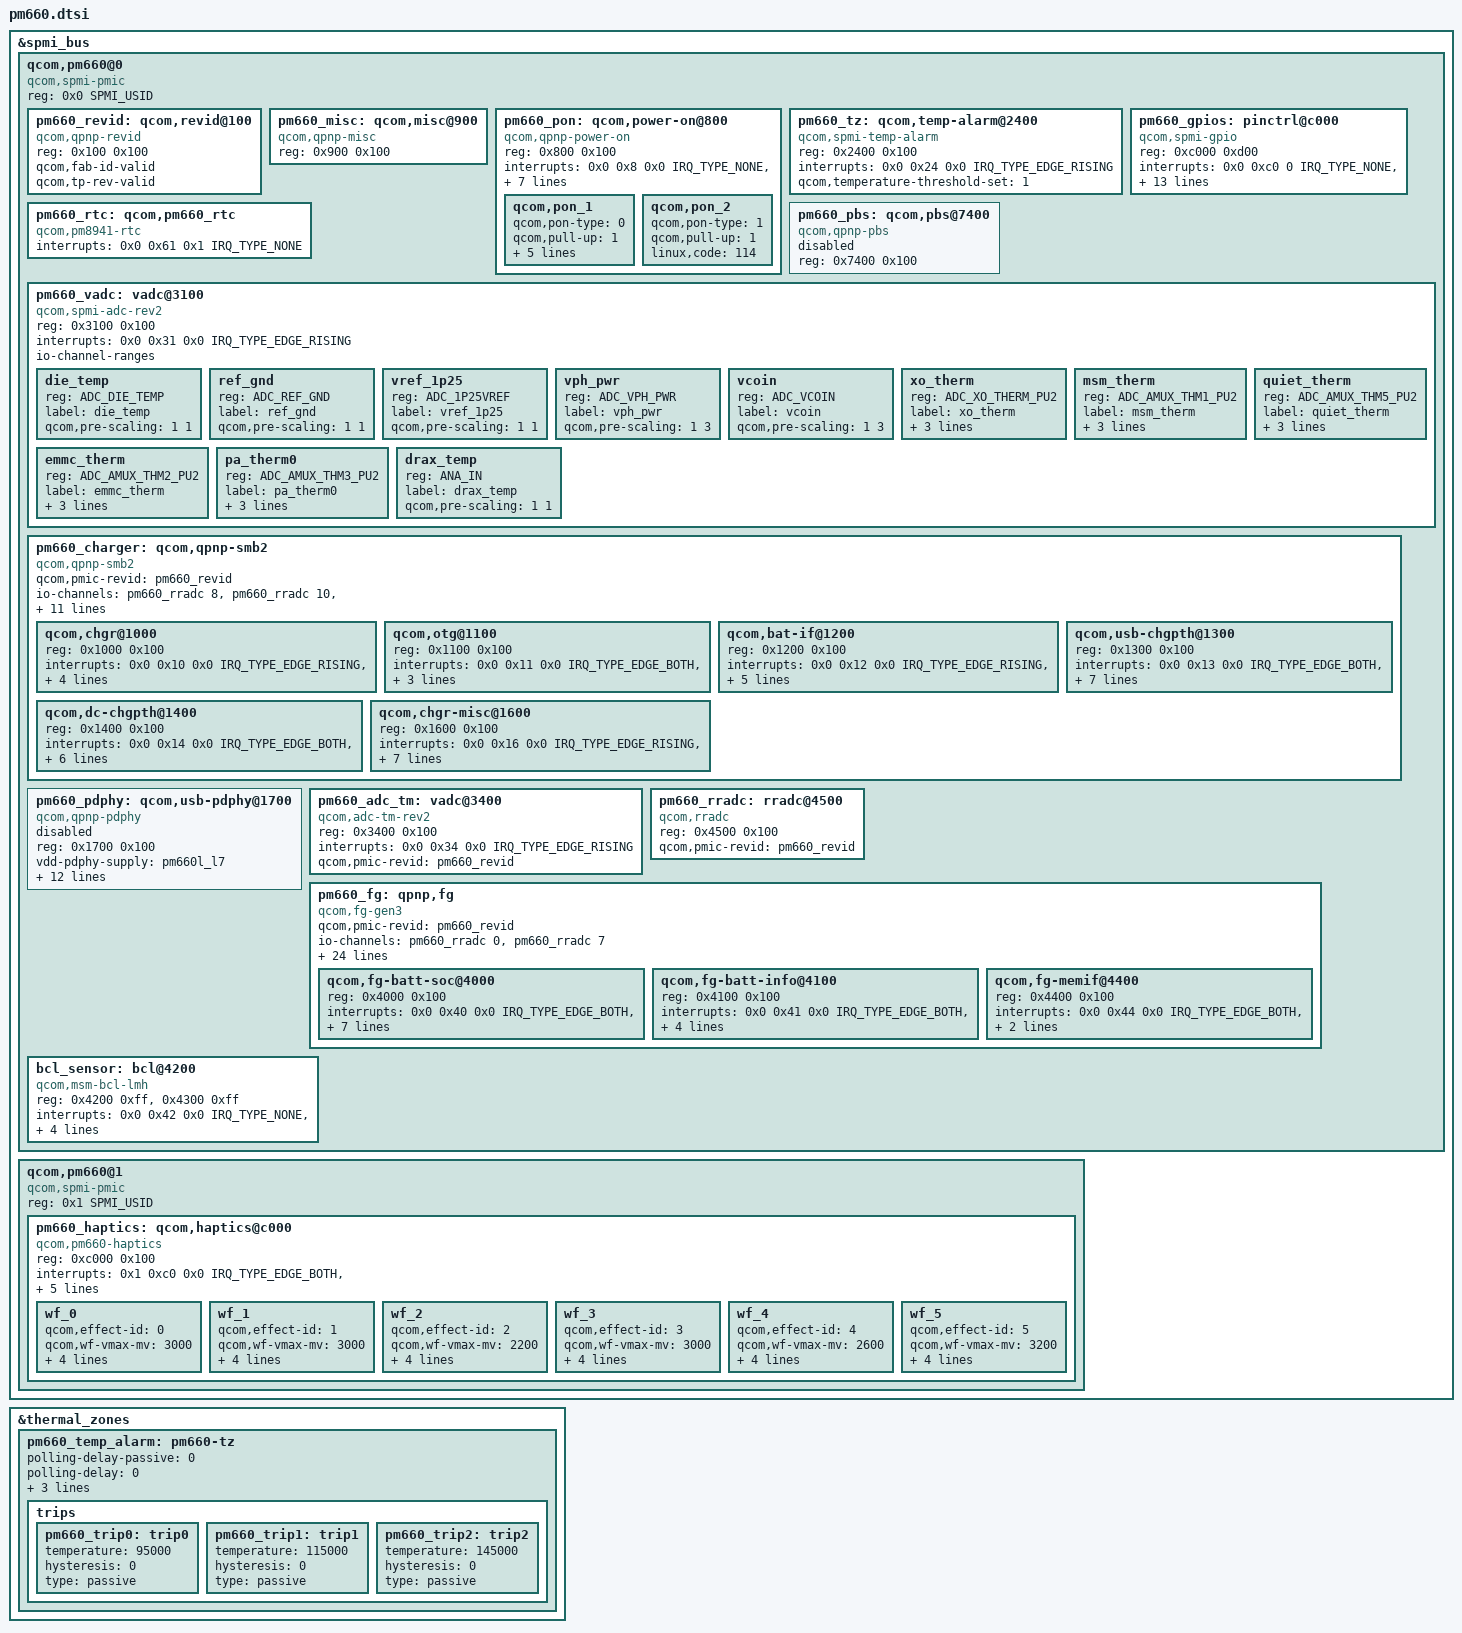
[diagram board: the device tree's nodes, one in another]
#include <dt-bindings/spmi/spmi.h>
#include <dt-bindings/iio/qcom,spmi-vadc.h>
#include <dt-bindings/interrupt-controller/irq.h>

&spmi_bus {
	qcom,pm660@0 {
		compatible ="qcom,spmi-pmic";
		reg = <0x0 SPMI_USID>;
		#address-cells = <2>;
		#size-cells = <0>;

		pm660_revid: qcom,revid@100 {
			compatible = "qcom,qpnp-revid";
			reg = <0x100 0x100>;
			qcom,fab-id-valid;
			qcom,tp-rev-valid;
		};

		pm660_misc: qcom,misc@900 {
			compatible = "qcom,qpnp-misc";
			reg = <0x900 0x100>;
		};

		pm660_pon: qcom,power-on@800 {
			compatible = "qcom,qpnp-power-on";
			reg = <0x800 0x100>;
			interrupts = <0x0 0x8 0x0 IRQ_TYPE_NONE>,
				     <0x0 0x8 0x1 IRQ_TYPE_NONE>,
				     <0x0 0x8 0x4 IRQ_TYPE_NONE>,
				     <0x0 0x8 0x5 IRQ_TYPE_NONE>;
			interrupt-names = "kpdpwr", "resin",
					"resin-bark", "kpdpwr-resin-bark";
			qcom,pon-dbc-delay = <15625>;
			qcom,kpdpwr-sw-debounce;
			qcom,system-reset;
			qcom,store-hard-reset-reason;

			qcom,pon_1 {
				qcom,pon-type = <0>;
				qcom,pull-up = <1>;
				linux,code = <116>;
			/* Huaqin add for ZQL1650-14 by lanshiming at 2018/1/17 start*/
				qcom,support-reset = <1>;
				qcom,s1-timer = <10256>;
				qcom,s2-timer = <10>;
				qcom,s2-type = <4>;
			/* Huaqin add for ZQL1650-14 by lanshiming at 2018/1/17 end*/
			};

			qcom,pon_2 {
				qcom,pon-type = <1>;
				qcom,pull-up = <1>;
				linux,code = <114>;
			};
		};

		pm660_tz: qcom,temp-alarm@2400 {
			compatible = "qcom,spmi-temp-alarm";
			reg = <0x2400 0x100>;
			interrupts = <0x0 0x24 0x0 IRQ_TYPE_EDGE_RISING>;
			#thermal-sensor-cells = <0>;
			qcom,temperature-threshold-set = <1>;
		};

		pm660_gpios: pinctrl@c000 {
			compatible = "qcom,spmi-gpio";
			reg = <0xc000 0xd00>;
			interrupts = <0x0 0xc0 0 IRQ_TYPE_NONE>,
					<0x0 0xc1 0 IRQ_TYPE_NONE>,
					<0x0 0xc2 0 IRQ_TYPE_NONE>,
					<0x0 0xc3 0 IRQ_TYPE_NONE>,
					<0x0 0xc4 0 IRQ_TYPE_NONE>,
					<0x0 0xc5 0 IRQ_TYPE_NONE>,
					<0x0 0xc6 0 IRQ_TYPE_NONE>,
					<0x0 0xc7 0 IRQ_TYPE_NONE>,
					<0x0 0xc8 0 IRQ_TYPE_NONE>,
					<0x0 0xc9 0 IRQ_TYPE_NONE>,
					<0x0 0xca 0 IRQ_TYPE_NONE>,
					<0x0 0xcb 0 IRQ_TYPE_NONE>,
					<0x0 0xcc 0 IRQ_TYPE_NONE>;
			interrupt-names = "pm660_gpio1", "pm660_gpio2",
					"pm660_gpio3", "pm660_gpio4",
					"pm660_gpio5", "pm660_gpio6",
					"pm660_gpio7", "pm660_gpio8",
					"pm660_gpio9", "pm660_gpio10",
					"pm660_gpio11", "pm660_gpio12",
					"pm660_gpio13";
			gpio-controller;
			#gpio-cells = <2>;
		};

		pm660_rtc: qcom,pm660_rtc {
			compatible = "qcom,pm8941-rtc";
			interrupts = <0x0 0x61 0x1 IRQ_TYPE_NONE>;
		};

		pm660_pbs: qcom,pbs@7400 {
			compatible = "qcom,qpnp-pbs";
			reg = <0x7400 0x100>;
			status = "disabled";
		};

		pm660_vadc: vadc@3100 {
			compatible = "qcom,spmi-adc-rev2";
			reg = <0x3100 0x100>;
			#address-cells = <1>;
			#size-cells = <0>;
			interrupts = <0x0 0x31 0x0 IRQ_TYPE_EDGE_RISING>;
			interrupt-names = "eoc-int-en-set";
			#io-channel-cells = <1>;
			io-channel-ranges;

			/* Channel nodes */
			die_temp {
				reg = <ADC_DIE_TEMP>;
				label = "die_temp";
				qcom,pre-scaling = <1 1>;
			};

			ref_gnd {
				reg = <ADC_REF_GND>;
				label = "ref_gnd";
				qcom,pre-scaling = <1 1>;
			};

			vref_1p25 {
				reg = <ADC_1P25VREF>;
				label = "vref_1p25";
				qcom,pre-scaling = <1 1>;
			};


			vph_pwr {
				reg = <ADC_VPH_PWR>;
				label = "vph_pwr";
				qcom,pre-scaling = <1 3>;
			};

			vcoin {
				reg = <ADC_VCOIN>;
				label = "vcoin";
				qcom,pre-scaling = <1 3>;
			};

			xo_therm {
				reg = <ADC_XO_THERM_PU2>;
				label = "xo_therm";
				qcom,ratiometric;
				qcom,hw-settle-time = <200>;
				qcom,pre-scaling = <1 1>;
			};

			msm_therm{
				reg = <ADC_AMUX_THM1_PU2>;
				label = "msm_therm";
				qcom,ratiometric;
				qcom,hw-settle-time = <200>;
				qcom,pre-scaling = <1 1>;
			};

			quiet_therm{
				reg = <ADC_AMUX_THM5_PU2>;
				label = "quiet_therm";
				qcom,ratiometric;
				qcom,hw-settle-time = <200>;
				qcom,pre-scaling = <1 1>;
			};

			emmc_therm{
				reg = <ADC_AMUX_THM2_PU2>;
				label = "emmc_therm";
				qcom,ratiometric;
				qcom,hw-settle-time = <200>;
				qcom,pre-scaling = <1 1>;
			};

			pa_therm0{
				reg = <ADC_AMUX_THM3_PU2>;
				label = "pa_therm0";
				qcom,ratiometric;
				qcom,hw-settle-time = <200>;
				qcom,pre-scaling = <1 1>;
			};

			drax_temp{
				reg = <ANA_IN>;
				label = "drax_temp";
				qcom,pre-scaling = <1 1>;
			};
		};

		pm660_charger: qcom,qpnp-smb2 {
			compatible = "qcom,qpnp-smb2";
			#address-cells = <1>;
			#size-cells = <1>;

			qcom,pmic-revid = <&pm660_revid>;

			io-channels = <&pm660_rradc 8>,
				      <&pm660_rradc 10>,
				      <&pm660_rradc 3>,
				      <&pm660_rradc 4>;
			io-channel-names = "charger_temp",
					   "charger_temp_max",
					   "usbin_i",
					   "usbin_v";

			qcom,wipower-max-uw = <5000000>;
			dpdm-supply = <&qusb_phy0>;

/* Huaqin modify for ZQL1650-70 Identify Adapter ID by fangaijun at 2018/02/8 start */
			qcom,thermal-mitigation
					= <3000000 2500000 2000000 1500000
						1000000 500000>;
/* Huaqin modify for ZQL1650-70 Identify Adapter ID by fangaijun at 2018/02/8 end */
			// Added by huqinmin remove Type-C for micro-usb 2018/1/31 begin
			qcom,use-extcon;
			// Added by huqinmin remove Type-C for micro-usb 2018/1/31 end
/* Huaqin modify for ZQL1650 by fangaijun  at 2018/02/2 start */
/* Huaqin modify for ZQL1650-70 optimize Adapter ID by fangaijun at 2018/02/9 start */
			qcom,fcc-max-ua = <2000000>;
/* Huaqin modify for ZQL1650-70 optimize Adapter ID by fangaijun at 2018/02/9 end */
			qcom,fv-max-uv = <4350000>;
/* Huaqin modify for ZQL1650-70 optimize Adapter ID by fangaijun at 2018/02/9 start */
			qcom,usb-icl-ua = <2000000>;
/* Huaqin modify for ZQL1650-70 optimize Adapter ID by fangaijun at 2018/02/9 end */
			qcom,float-option = <1>;
/* Huaqin modify for ZQL1650 by fangaijun  at 2018/02/2 end */
/* Huaqin modify for ZQL1650 recharge SOC and voltage by fangaijun at 2018/02/2 start */
			qcom,auto-recharge-soc;
/* Huaqin modify for ZQL1650 recharge SOC and voltage by fangaijun at 2018/02/2 end */
			qcom,chgr@1000 {
				reg = <0x1000 0x100>;
				interrupts =
					<0x0 0x10 0x0 IRQ_TYPE_EDGE_RISING>,
					<0x0 0x10 0x1 IRQ_TYPE_EDGE_RISING>,
					<0x0 0x10 0x2 IRQ_TYPE_EDGE_RISING>,
					<0x0 0x10 0x3 IRQ_TYPE_EDGE_RISING>,
					<0x0 0x10 0x4 IRQ_TYPE_EDGE_RISING>;

				interrupt-names = "chg-error",
						  "chg-state-change",
						  "step-chg-state-change",
						  "step-chg-soc-update-fail",
						  "step-chg-soc-update-request";
			};

			qcom,otg@1100 {
				reg = <0x1100 0x100>;
				interrupts = <0x0 0x11 0x0 IRQ_TYPE_EDGE_BOTH>,
					     <0x0 0x11 0x1 IRQ_TYPE_EDGE_BOTH>,
					     <0x0 0x11 0x2 IRQ_TYPE_EDGE_BOTH>,
					     <0x0 0x11 0x3 IRQ_TYPE_EDGE_BOTH>;

				interrupt-names = "otg-fail",
						  "otg-overcurrent",
						  "otg-oc-dis-sw-sts",
						  "testmode-change-detect";
			};

			qcom,bat-if@1200 {
				reg = <0x1200 0x100>;
				interrupts =
					<0x0 0x12 0x0 IRQ_TYPE_EDGE_RISING>,
					<0x0 0x12 0x1 IRQ_TYPE_EDGE_BOTH>,
					<0x0 0x12 0x2 IRQ_TYPE_EDGE_BOTH>,
					<0x0 0x12 0x3 IRQ_TYPE_EDGE_BOTH>,
					<0x0 0x12 0x4 IRQ_TYPE_EDGE_BOTH>,
					<0x0 0x12 0x5 IRQ_TYPE_EDGE_BOTH>;

				interrupt-names = "bat-temp",
						  "bat-ocp",
						  "bat-ov",
						  "bat-low",
						  "bat-therm-or-id-missing",
						  "bat-terminal-missing";
			};

			qcom,usb-chgpth@1300 {
				reg = <0x1300 0x100>;
				interrupts =
					<0x0 0x13 0x0 IRQ_TYPE_EDGE_BOTH>,
					<0x0 0x13 0x1 IRQ_TYPE_EDGE_BOTH>,
					<0x0 0x13 0x2 IRQ_TYPE_EDGE_BOTH>,
					<0x0 0x13 0x3 IRQ_TYPE_EDGE_BOTH>,
					<0x0 0x13 0x4 IRQ_TYPE_EDGE_BOTH>,
					<0x0 0x13 0x5 IRQ_TYPE_EDGE_RISING>,
					<0x0 0x13 0x6 IRQ_TYPE_EDGE_RISING>,
					<0x0 0x13 0x7 IRQ_TYPE_EDGE_RISING>;

				interrupt-names = "usbin-collapse",
						  "usbin-lt-3p6v",
						  "usbin-uv",
						  "usbin-ov",
						  "usbin-plugin",
						  "usbin-src-change",
						  "usbin-icl-change",
						  "type-c-change";
			};

			qcom,dc-chgpth@1400 {
				reg = <0x1400 0x100>;
				interrupts =
					<0x0 0x14 0x0 IRQ_TYPE_EDGE_BOTH>,
					<0x0 0x14 0x1 IRQ_TYPE_EDGE_BOTH>,
					<0x0 0x14 0x2 IRQ_TYPE_EDGE_BOTH>,
					<0x0 0x14 0x3 IRQ_TYPE_EDGE_BOTH>,
					<0x0 0x14 0x4 IRQ_TYPE_EDGE_BOTH>,
					<0x0 0x14 0x5 IRQ_TYPE_EDGE_BOTH>,
					<0x0 0x14 0x6 IRQ_TYPE_EDGE_RISING>;

				interrupt-names = "dcin-collapse",
						  "dcin-lt-3p6v",
						  "dcin-uv",
						  "dcin-ov",
						  "dcin-plugin",
						  "div2-en-dg",
						  "dcin-icl-change";
			};

			qcom,chgr-misc@1600 {
				reg = <0x1600 0x100>;
				interrupts =
					<0x0 0x16 0x0 IRQ_TYPE_EDGE_RISING>,
					<0x0 0x16 0x1 IRQ_TYPE_EDGE_RISING>,
					<0x0 0x16 0x2 IRQ_TYPE_EDGE_BOTH>,
					<0x0 0x16 0x3 IRQ_TYPE_EDGE_BOTH>,
					<0x0 0x16 0x4 IRQ_TYPE_EDGE_BOTH>,
					<0x0 0x16 0x5 IRQ_TYPE_EDGE_BOTH>,
					<0x0 0x16 0x6 IRQ_TYPE_EDGE_FALLING>,
					<0x0 0x16 0x7 IRQ_TYPE_EDGE_BOTH>;

				interrupt-names = "wdog-snarl",
						  "wdog-bark",
						  "aicl-fail",
						  "aicl-done",
						  "high-duty-cycle",
						  "input-current-limiting",
						  "temperature-change",
						  "switcher-power-ok";
			};
		};

		pm660_pdphy: qcom,usb-pdphy@1700 {
			compatible = "qcom,qpnp-pdphy";
			// Added by huqinmin remove Type-C for micro-usb 2018/1/31 begin
			/* Huaqin modify for ZQL1820-HQ000003 Optimize power consumption by diabling TYPE-C by gaochao at 2018/09/17 start */
			status = "disabled";
			/* Huaqin modify for ZQL1820-HQ000003 Optimize power consumption by diabling TYPE-C by gaochao at 2018/09/17 end */
			// Added by huqinmin remove Type-C for micro-usb 2018/1/31 end
			reg = <0x1700 0x100>;
			vdd-pdphy-supply = <&pm660l_l7>;
			vbus-supply = <&smb2_vbus>;
			vconn-supply = <&smb2_vconn>;
			interrupts = <0x0 0x17 0x0 IRQ_TYPE_EDGE_RISING>,
				     <0x0 0x17 0x1 IRQ_TYPE_EDGE_RISING>,
				     <0x0 0x17 0x2 IRQ_TYPE_EDGE_RISING>,
				     <0x0 0x17 0x3 IRQ_TYPE_EDGE_RISING>,
				     <0x0 0x17 0x4 IRQ_TYPE_EDGE_RISING>,
				     <0x0 0x17 0x5 IRQ_TYPE_EDGE_RISING>,
				     <0x0 0x17 0x6 IRQ_TYPE_EDGE_RISING>;

			interrupt-names = "sig-tx",
					  "sig-rx",
					  "msg-tx",
					  "msg-rx",
					  "msg-tx-failed",
					  "msg-tx-discarded",
					  "msg-rx-discarded";

			qcom,default-sink-caps = <5000 3000>, /* 5V @ 3A */
						 <9000 3000>; /* 9V @ 3A */
			qcom,no-usb3-dp-concurrency;
			qcom,pd-20-source-only;
		};

		pm660_adc_tm: vadc@3400 {
			compatible = "qcom,adc-tm-rev2";
			reg = <0x3400 0x100>;
			interrupts = <0x0 0x34 0x0 IRQ_TYPE_EDGE_RISING>;
			interrupt-names = "thr-int-en";
			#address-cells = <1>;
			#size-cells = <0>;
			#thermal-sensor-cells = <1>;
			qcom,pmic-revid = <&pm660_revid>;
		};

		pm660_rradc: rradc@4500 {
			compatible = "qcom,rradc";
			reg = <0x4500 0x100>;
			#address-cells = <1>;
			#size-cells = <0>;
			#io-channel-cells = <1>;
			qcom,pmic-revid = <&pm660_revid>;
		};

		pm660_fg: qpnp,fg {
			compatible = "qcom,fg-gen3";
			#address-cells = <1>;
			#size-cells = <1>;
			qcom,pmic-revid = <&pm660_revid>;
			io-channels = <&pm660_rradc 0>,
				      <&pm660_rradc 7>;
			io-channel-names = "rradc_batt_id",
					   "rradc_die_temp";
			qcom,rradc-base = <0x4500>;
			qcom,fg-esr-timer-awake = <96 96>;
/* Huaqin modify for ZQL1650-1244 A periodic pulse of 14s occurs when the phone idel by fangaijun  at 2018/05/14 start */
			qcom,fg-esr-timer-asleep = <160 256>;
/* Huaqin modify for ZQL1650-1244 A periodic pulse of 14s occurs when the phone idel by fangaijun  at 2018/05/14 end */
			qcom,fg-esr-timer-charging = <0 96>;
			qcom,cycle-counter-en;
/* Huaqin modify for ZQL1650 by fangaijun  at 2018/02/1 start */
			qcom,fg-cutoff-voltage = <3400>;
			qcom,fg-empty-voltage = <2800>;
/* Huaqin modify for ZQL1650 by fangaijun  at 2018/02/1 end */

/* Huaqin modify for ZQL1650 remove cc-cv voltage by fangaijun  at 2018/03/22 start */
			//qcom,fg-cc-cv-threshold-mv = <4340>;
/* Huaqin modify for ZQL1650 remove cc-cv voltage by fangaijun  at 2018/03/22 end */
/* Huaqin modify for ZQL1650-586 optimize low temperature discharging soc deviation by fangaijun  at 2018/03/22 start */
/* Huaqin modify for ZQL1650-1096 optimize normal temperature charging soc deviation by fangaijun  at 2018/04/27 start */
			qcom,fg-esr-tight-filter-micro-pct = <20000>;
			qcom,fg-esr-broad-filter-micro-pct = <25000>;
/* Huaqin modify for ZQL1650-1096 optimize normal temperature charging soc deviation by fangaijun  at 2018/04/27 end */
			qcom,fg-esr-tight-lt-filter-micro-pct = <2000>;
			qcom,fg-esr-broad-lt-filter-micro-pct = <2200>;
			qcom,slope-limit-temp-threshold = <150>;
			qcom,slope-limit-coeffs = <1 1 1 1>;
/* Huaqin modify for ZQL1650-586 optimize low temperature discharging soc deviation by fangaijun  at 2018/03/22 end */
/* Huaqin modify for ZQL1650 by fangaijun  at 2018/02/2 start */
			qcom,fg-chg-term-current = <150>;
			qcom,fg-sys-term-current = <(-200)>;
			qcom,hold-soc-while-full;
			qcom,linearize-soc;
			qcom,fg-force-load-profile;
/* Huaqin modify for ZQL1650 Realize HW Jeita by fangaijun  at 2018/02/6 start */
			/* Huaqin modify for ZQL1820-HQ000002  Adjust JEITA according to customer require by gaochao at 2018/10/11 start */
			//qcom,fg-jeita-thresholds = <0 1 59 60>;
			qcom,fg-jeita-thresholds = <0 1 54 55>;
			/* Huaqin modify for ZQL1820-HQ000002  Adjust JEITA according to customer require by gaochao at 2018/10/11 end */
			qcom,fg-jeita-hyst-temp = <3>;
/* Huaqin modify for ZQL1650 Realize HW Jeita by fangaijun  at 2018/02/6 end */
/* Huaqin modify for ZQL1650 by fangaijun  at 2018/02/2 end */
/* Huaqin modify for ZQL1650 recharge SOC and voltage by fangaijun at 2018/02/2 start */
			qcom,fg-recharge-voltage = <4150>;
			qcom,fg-recharge-soc-thr = <98>;
			qcom,fg-auto-recharge-soc;
/* Huaqin modify for ZQL1650 recharge SOC and voltage by fangaijun at 2018/02/2 end */
//Huaqin added by tangqingyong at 20180226 for fg use external start
			qcom,fg-rsense-sel=<1>;
//Huaqin added by tangqingyong at 20180226 for fg use external end
			status = "okay";

			qcom,fg-batt-soc@4000 {
				status = "okay";
				reg = <0x4000 0x100>;
				interrupts = <0x0 0x40 0x0 IRQ_TYPE_EDGE_BOTH>,
					     <0x0 0x40 0x1 IRQ_TYPE_EDGE_BOTH>,
					     <0x0 0x40 0x2
							IRQ_TYPE_EDGE_RISING>,
					     <0x0 0x40 0x3
							IRQ_TYPE_EDGE_RISING>,
					     <0x0 0x40 0x4 IRQ_TYPE_EDGE_BOTH>,
					     <0x0 0x40 0x5
							IRQ_TYPE_EDGE_RISING>,
					     <0x0 0x40 0x6 IRQ_TYPE_EDGE_BOTH>,
					     <0x0 0x40 0x7 IRQ_TYPE_EDGE_BOTH>;
				interrupt-names = "soc-update",
						  "soc-ready",
						  "bsoc-delta",
						  "msoc-delta",
						  "msoc-low",
						  "msoc-empty",
						  "msoc-high",
						  "msoc-full";
			};

			qcom,fg-batt-info@4100 {
				status = "okay";
				reg = <0x4100 0x100>;
				interrupts = <0x0 0x41 0x0 IRQ_TYPE_EDGE_BOTH>,
					     <0x0 0x41 0x1 IRQ_TYPE_EDGE_BOTH>,
					     <0x0 0x41 0x2 IRQ_TYPE_EDGE_BOTH>,
					     <0x0 0x41 0x3 IRQ_TYPE_EDGE_BOTH>,
					     <0x0 0x41 0x6 IRQ_TYPE_EDGE_BOTH>;
				interrupt-names = "vbatt-pred-delta",
						  "vbatt-low",
						  "esr-delta",
						  "batt-missing",
						  "batt-temp-delta";
			};

			qcom,fg-memif@4400 {
				status = "okay";
				reg = <0x4400 0x100>;
				interrupts = <0x0 0x44 0x0 IRQ_TYPE_EDGE_BOTH>,
					     <0x0 0x44 0x1 IRQ_TYPE_EDGE_BOTH>,
					     <0x0 0x44 0x2 IRQ_TYPE_EDGE_BOTH>;
				interrupt-names = "ima-rdy",
						  "mem-xcp",
						  "dma-grant";
			};
		};

		bcl_sensor:bcl@4200 {
			compatible = "qcom,msm-bcl-lmh";
			reg = <0x4200 0xff>,
				<0x4300 0xff>;
			reg-names = "fg_user_adc",
					"fg_lmh";
			interrupts = <0x0 0x42 0x0 IRQ_TYPE_NONE>,
					<0x0 0x42 0x1 IRQ_TYPE_NONE>,
					<0x0 0x42 0x2 IRQ_TYPE_NONE>,
					<0x0 0x42 0x3 IRQ_TYPE_NONE>,
					<0x0 0x42 0x4 IRQ_TYPE_NONE>;
			interrupt-names = "bcl-high-ibat",
						"bcl-very-high-ibat",
						"bcl-low-vbat",
						"bcl-very-low-vbat",
						"bcl-crit-low-vbat";
			#thermal-sensor-cells = <1>;
		};
	};

	qcom,pm660@1 {
		compatible ="qcom,spmi-pmic";
		reg = <0x1 SPMI_USID>;
		#address-cells = <2>;
		#size-cells = <0>;

		pm660_haptics: qcom,haptics@c000 {
			compatible = "qcom,pm660-haptics";
			reg = <0xc000 0x100>;
			reg-names = "haptics";
			status = "okay";

			interrupts = <0x1 0xc0 0x0 IRQ_TYPE_EDGE_BOTH>,
				     <0x1 0xc0 0x1 IRQ_TYPE_EDGE_BOTH>;
			interrupt-names = "hap-sc-irq", "hap-play-irq";

			qcom,actuator-type = "erm"; 
			qcom,vmax-mv = <3000>;
			qcom,play-rate-us = <5715>;
			qcom,max-play-time-ms = <15000>;

			/* 0: CLICK */
			wf_0 {
				qcom,effect-id = <0>;
				qcom,wf-vmax-mv = <3000>;
				qcom,wf-pattern = /bits/ 8 <0x3e 0x3e 0x3e>;
				qcom,wf-play-rate-us = <5715>;
				qcom,wf-repeat-count = <1>;
				qcom,wf-s-repeat-count = <1>;
			};

			/* 1: DOUBLE CLICK */
			wf_1 {
				qcom,effect-id = <1>;
				qcom,wf-vmax-mv = <3000>;
				qcom,wf-pattern = /bits/ 8 <0x7e 0x7e 0x00 0x00 0x7e 0x7e>;
				qcom,wf-play-rate-us = <5715>;
				qcom,wf-repeat-count = <1>;
				qcom,wf-s-repeat-count = <1>;
			};

			/* 2: TICK (Мягкий клик клавиатуры/скролла) */
			wf_2 {
				qcom,effect-id = <2>;
				qcom,wf-vmax-mv = <2200>;
				qcom,wf-pattern = /bits/ 8 <0x40 0x00>;
				qcom,wf-play-rate-us = <4000>;
				qcom,wf-repeat-count = <1>;
				qcom,wf-s-repeat-count = <1>;
			};

			/* 3: THUD */
			wf_3 {
				qcom,effect-id = <3>;
				qcom,wf-vmax-mv = <3000>;
				qcom,wf-pattern = /bits/ 8 <0x7e 0x7e 0x7e>;
				qcom,wf-play-rate-us = <5715>;
				qcom,wf-repeat-count = <1>;
				qcom,wf-s-repeat-count = <1>;
			};

			/* 4: POP */
			wf_4 {
				qcom,effect-id = <4>;
				qcom,wf-vmax-mv = <2600>;
				qcom,wf-pattern = /bits/ 8 <0x60 0x00>;
				qcom,wf-play-rate-us = <5000>;
				qcom,wf-repeat-count = <1>;
				qcom,wf-s-repeat-count = <1>;
			};

			/* 5: HEAVY CLICK (Сильный щелчок) */
			wf_5 {
				qcom,effect-id = <5>;
				qcom,wf-vmax-mv = <3200>;
				qcom,wf-pattern = /bits/ 8 <0x7e 0x7e 0x7e 0x7e>;
				qcom,wf-play-rate-us = <5715>;
				qcom,wf-repeat-count = <1>;
				qcom,wf-s-repeat-count = <1>;
			};
		};
	};
};

&thermal_zones {
	pm660_temp_alarm: pm660-tz {
		polling-delay-passive = <0>;
		polling-delay = <0>;
		thermal-governor = "step_wise";
		thermal-sensors = <&pm660_tz>;
		wake-capable-sensor;

		trips {
			pm660_trip0: trip0 {
				temperature = <95000>;
				hysteresis = <0>;
				type = "passive";
			};
			pm660_trip1: trip1 {
				temperature = <115000>;
				hysteresis = <0>;
				type = "passive";
			};
			pm660_trip2: trip2 {
				temperature = <145000>;
				hysteresis = <0>;
				type = "passive";
			};
		};
	};
};
